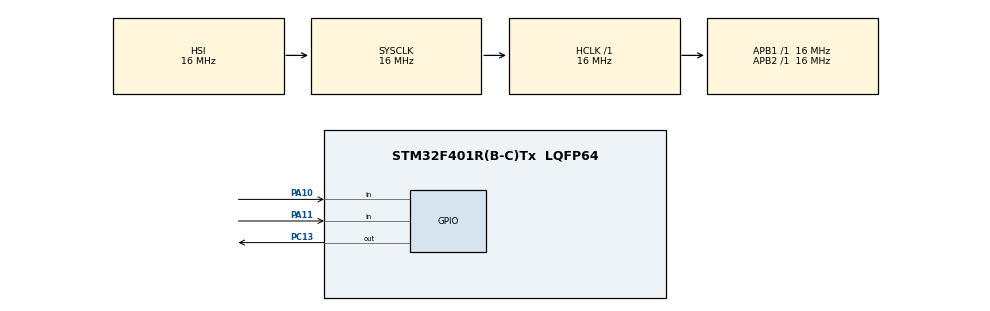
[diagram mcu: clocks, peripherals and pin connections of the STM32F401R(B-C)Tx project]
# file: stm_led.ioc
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Mcu.Family=STM32F4
Mcu.Name=STM32F401R(B-C)Tx
Mcu.Package=LQFP64
NVIC.PriorityGroup=NVIC_PRIORITYGROUP_4
NVIC.TIM2_IRQn=true\:0\:0\:false\:false\:true\:true\:true\:true
PA10.GPIO_PuPd=GPIO_PULLDOWN
PA10.Signal=GPIO_Input
PA11.GPIO_PuPd=GPIO_PULLDOWN
PA11.Signal=GPIO_Input
PC13-ANTI_TAMP.Signal=GPIO_Output
ProjectManager.HeapSize=0x200
ProjectManager.StackSize=0x400
ProjectManager.TargetToolchain=STM32CubeIDE
RCC.48MHZClocksFreq_Value=48000000
RCC.AHBFreq_Value=16000000
RCC.APB1Freq_Value=16000000
RCC.APB2Freq_Value=16000000
RCC.CortexFreq_Value=16000000
RCC.HSE_VALUE=25000000
RCC.HSI_VALUE=16000000
RCC.LSE_VALUE=32768
RCC.SYSCLKFreq_VALUE=16000000
RCC.VCOOutputFreq_Value=192000000
TIM2.Period=99
TIM2.Prescaler=15
VP_TIM2_VS_ClockSourceINT.Mode=Internal
board=custom

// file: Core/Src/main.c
/* USER CODE BEGIN Header */
/**
  ******************************************************************************
  * @file           : main.c
  * @brief          : Main program body
  ******************************************************************************
  * @attention
  *
  * Copyright (c) 2026 STMicroelectronics.
  * All rights reserved.
  *
  * This software is licensed under terms that can be found in the LICENSE file
  * in the root directory of this software component.
  * If no LICENSE file comes with this software, it is provided AS-IS.
  *
  ******************************************************************************
  */
/* USER CODE END Header */
#include "main.h"

TIM_HandleTypeDef htim2;

void SystemClock_Config(void);
static void MX_GPIO_Init(void);
static void MX_TIM2_Init(void);

/* USER CODE BEGIN 0 */
volatile int pwm_counter = 0;
volatile int brightness = 0;  // 0 to 100

void breathe_led(uint32_t current_tick)
{
    // static variables remember their value between function calls
    static uint32_t last_breathe_tick = 0;
    static int fadeAmount = 1;

    // Smoothly adjust brightness every 10ms without blocking
    if (current_tick - last_breathe_tick >= 10) {
        last_breathe_tick = current_tick;

        brightness += fadeAmount;

        // Hard-clamp the boundaries so it cannot get stuck
        if (brightness >= 100) {
            brightness = 100;
            fadeAmount = -1; // Force it to fade down
        }
        else if (brightness <= 0) {
            brightness = 0;
            fadeAmount = 1;  // Force it to fade up
        }
    }
}

void change_led(uint32_t current_tick, uint8_t dc_idx)
{
    const uint8_t duty_cycles[] = {10, 30, 50, 70, 90};
    uint32_t period_ms = 500;
    uint32_t on_time = (period_ms * duty_cycles[dc_idx]) / 100;

    if ((current_tick % period_ms) < on_time) {
        brightness = 100;
    } else {
        brightness = 0;
    }
}

typedef enum {
    BTN_NONE = 0,
    BTN_PRESSED,
    BTN_HELD,
    BTN_RELEASED
} ButtonEvent;

ButtonEvent get_button_event(uint8_t current_state, uint8_t* last_state)
{
    ButtonEvent event = BTN_NONE;

    if (current_state == GPIO_PIN_SET && *last_state == GPIO_PIN_RESET) {
        event = BTN_PRESSED;
    }
    else if (current_state == GPIO_PIN_SET && *last_state == GPIO_PIN_SET) {
        event = BTN_HELD;
    }
    else if (current_state == GPIO_PIN_RESET && *last_state == GPIO_PIN_SET) {
        event = BTN_RELEASED;
    }

    *last_state = current_state;
    return event;
}
/* USER CODE END 0 */

int main(void)
{

  /* MCU Configuration--------------------------------------------------------*/

  /* Reset of all peripherals, Initializes the Flash interface and the Systick. */
  HAL_Init();

  /* Configure the system clock */
  SystemClock_Config();

  /* Initialize all configured peripherals */
  MX_GPIO_Init();
  MX_TIM2_Init();
  /* USER CODE BEGIN 2 */
    HAL_NVIC_SetPriority(TIM2_IRQn, 0, 0);
    HAL_NVIC_EnableIRQ(TIM2_IRQn);
    HAL_TIM_Base_Start_IT(&htim2);

    uint8_t last_change_btn = 0;
    uint8_t dc_idx = 1;
    uint32_t last_button_check = 0;

    typedef enum { BLINKING, BREATHING } SystemState;
    SystemState state = BLINKING;
    /* USER CODE END 2 */
  /* USER CODE END 2 */

  /* Infinite loop */
  while (1)
  {

    /* USER CODE BEGIN 3 */
	  /* USER CODE BEGIN 3 */
		uint32_t current_tick = HAL_GetTick();

		// --- 1. DEBOUNCER (read switches every 20ms) ---
		if (current_tick - last_button_check >= 20) {
			last_button_check = current_tick;

			uint8_t change_btn = HAL_GPIO_ReadPin(GPIOA, GPIO_PIN_10);
			uint8_t breathe_btn = HAL_GPIO_ReadPin(GPIOA, GPIO_PIN_11);

			ButtonEvent change_event = get_button_event(change_btn, &last_change_btn);

			// Switch state based on resting position of Breathe switch
			if (breathe_btn == GPIO_PIN_SET) {
				state = BREATHING;
			} else {
				state = BLINKING;
			}

			// Advance duty cycle when Change switch is flipped in EITHER direction
			if (change_event == BTN_PRESSED || change_event == BTN_RELEASED) {
				dc_idx++;
				if (dc_idx > 4) dc_idx = 0;
			}
		}

		// --- 2. CONTINUOUS LED EXECUTION ---
		if (state == BREATHING) {
			breathe_led(current_tick);
		} else {
			change_led(current_tick, dc_idx);
		}
	}
	/* USER CODE END 3 */

}

void SystemClock_Config(void)
{
  RCC_OscInitTypeDef RCC_OscInitStruct = {0};
  RCC_ClkInitTypeDef RCC_ClkInitStruct = {0};

  /** Configure the main internal regulator output voltage
  */
  __HAL_RCC_PWR_CLK_ENABLE();
  __HAL_PWR_VOLTAGESCALING_CONFIG(PWR_REGULATOR_VOLTAGE_SCALE2);

  /** Initializes the RCC Oscillators according to the specified parameters
  * in the RCC_OscInitTypeDef structure.
  */
  RCC_OscInitStruct.OscillatorType = RCC_OSCILLATORTYPE_HSI;
  RCC_OscInitStruct.HSIState = RCC_HSI_ON;
  RCC_OscInitStruct.HSICalibrationValue = RCC_HSICALIBRATION_DEFAULT;
  RCC_OscInitStruct.PLL.PLLState = RCC_PLL_NONE;
  if (HAL_RCC_OscConfig(&RCC_OscInitStruct) != HAL_OK)
  {
    Error_Handler();
  }

  /** Initializes the CPU, AHB and APB buses clocks
  */
  RCC_ClkInitStruct.ClockType = RCC_CLOCKTYPE_HCLK|RCC_CLOCKTYPE_SYSCLK
                              |RCC_CLOCKTYPE_PCLK1|RCC_CLOCKTYPE_PCLK2;
  RCC_ClkInitStruct.SYSCLKSource = RCC_SYSCLKSOURCE_HSI;
  RCC_ClkInitStruct.AHBCLKDivider = RCC_SYSCLK_DIV1;
  RCC_ClkInitStruct.APB1CLKDivider = RCC_HCLK_DIV1;
  RCC_ClkInitStruct.APB2CLKDivider = RCC_HCLK_DIV1;

  if (HAL_RCC_ClockConfig(&RCC_ClkInitStruct, FLASH_LATENCY_0) != HAL_OK)
  {
    Error_Handler();
  }
}

static void MX_TIM2_Init(void)
{

  TIM_ClockConfigTypeDef sClockSourceConfig = {0};
  TIM_MasterConfigTypeDef sMasterConfig = {0};

  htim2.Instance = TIM2;
  htim2.Init.Prescaler = 15;
  htim2.Init.CounterMode = TIM_COUNTERMODE_UP;
  htim2.Init.Period = 99;
  htim2.Init.ClockDivision = TIM_CLOCKDIVISION_DIV1;
  htim2.Init.AutoReloadPreload = TIM_AUTORELOAD_PRELOAD_DISABLE;
  if (HAL_TIM_Base_Init(&htim2) != HAL_OK)
  {
    Error_Handler();
  }
  sClockSourceConfig.ClockSource = TIM_CLOCKSOURCE_INTERNAL;
  if (HAL_TIM_ConfigClockSource(&htim2, &sClockSourceConfig) != HAL_OK)
  {
    Error_Handler();
  }
  sMasterConfig.MasterOutputTrigger = TIM_TRGO_RESET;
  sMasterConfig.MasterSlaveMode = TIM_MASTERSLAVEMODE_DISABLE;
  if (HAL_TIMEx_MasterConfigSynchronization(&htim2, &sMasterConfig) != HAL_OK)
  {
    Error_Handler();
  }

}

static void MX_GPIO_Init(void)
{
  GPIO_InitTypeDef GPIO_InitStruct = {0};

  /* GPIO Ports Clock Enable */
  __HAL_RCC_GPIOC_CLK_ENABLE();
  __HAL_RCC_GPIOA_CLK_ENABLE();

  /*Configure GPIO pin Output Level */
  HAL_GPIO_WritePin(GPIOC, GPIO_PIN_13, GPIO_PIN_RESET);

  /*Configure GPIO pin : PC13 */
  GPIO_InitStruct.Pin = GPIO_PIN_13;
  GPIO_InitStruct.Mode = GPIO_MODE_OUTPUT_PP;
  GPIO_InitStruct.Pull = GPIO_NOPULL;
  GPIO_InitStruct.Speed = GPIO_SPEED_FREQ_LOW;
  HAL_GPIO_Init(GPIOC, &GPIO_InitStruct);

  /*Configure GPIO pins : PA10 PA11 */
  GPIO_InitStruct.Pin = GPIO_PIN_10|GPIO_PIN_11;
  GPIO_InitStruct.Mode = GPIO_MODE_INPUT;
  GPIO_InitStruct.Pull = GPIO_PULLDOWN;
  HAL_GPIO_Init(GPIOA, &GPIO_InitStruct);

}

/* USER CODE BEGIN 4 */
void HAL_TIM_PeriodElapsedCallback(TIM_HandleTypeDef *htim)
{
    if (htim->Instance == TIM2) {
        if (pwm_counter < brightness) {
            HAL_GPIO_WritePin(GPIOC, GPIO_PIN_13, GPIO_PIN_RESET);
        } else {
            HAL_GPIO_WritePin(GPIOC, GPIO_PIN_13, GPIO_PIN_SET);
        }

        pwm_counter++;
        if (pwm_counter >= 100) {
            pwm_counter = 0;
        }
    }
}

/* USER CODE END 4 */

void Error_Handler(void)
{
  __disable_irq();
  while (1)
  {
  }
}
